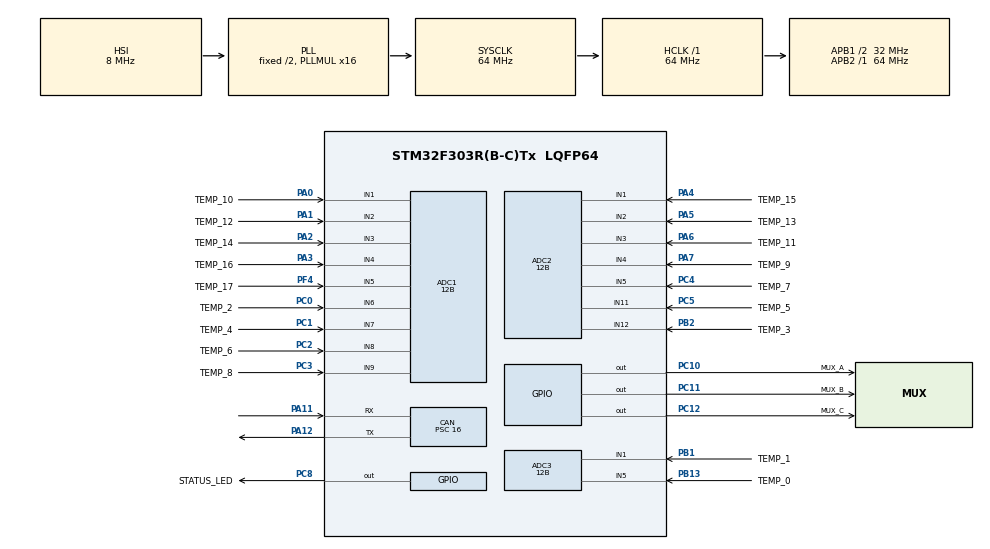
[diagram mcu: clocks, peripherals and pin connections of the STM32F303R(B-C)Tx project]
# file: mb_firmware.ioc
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ADC1.Channel-0\#ChannelRegularConversion=ADC_CHANNEL_6
ADC1.Channel-1\#ChannelRegularConversion=ADC_CHANNEL_7
ADC1.Channel-2\#ChannelRegularConversion=ADC_CHANNEL_8
ADC1.Channel-3\#ChannelRegularConversion=ADC_CHANNEL_9
ADC1.Channel-4\#ChannelRegularConversion=ADC_CHANNEL_1
ADC1.Channel-5\#ChannelRegularConversion=ADC_CHANNEL_2
ADC1.Channel-6\#ChannelRegularConversion=ADC_CHANNEL_3
ADC1.Channel-7\#ChannelRegularConversion=ADC_CHANNEL_4
ADC1.Channel-8\#ChannelRegularConversion=ADC_CHANNEL_5
ADC1.ClockPrescaler=ADC_CLOCK_ASYNC_DIV1
ADC1.ContinuousConvMode=DISABLE
ADC1.DMAContinuousRequests=DISABLE
ADC1.DataAlign=ADC_DATAALIGN_RIGHT
ADC1.DiscontinuousConvMode=DISABLE
ADC1.EOCSelection=ADC_EOC_SEQ_CONV
ADC1.EnableAnalogWatchDog1=false
ADC1.EnableAnalogWatchDog2=false
ADC1.EnableAnalogWatchDog3=false
ADC1.EnableInjectedConversion=ENABLE
ADC1.EnableRegularConversion=ENABLE
ADC1.ExternalTrigConv=ADC_SOFTWARE_START
ADC1.ExternalTrigConvEdge=ADC_EXTERNALTRIGCONVEDGE_NONE
ADC1.InjNumberOfConversion=0
ADC1.LowPowerAutoWait=DISABLE
ADC1.NbrOfConversion=9
ADC1.NbrOfConversionFlag=1
ADC1.Offset-0\#ChannelRegularConversion=0
ADC1.Offset-1\#ChannelRegularConversion=0
ADC1.Offset-2\#ChannelRegularConversion=0
ADC1.Offset-3\#ChannelRegularConversion=0
ADC1.Offset-4\#ChannelRegularConversion=0
ADC1.Offset-5\#ChannelRegularConversion=0
ADC1.Offset-6\#ChannelRegularConversion=0
ADC1.Offset-7\#ChannelRegularConversion=0
ADC1.Offset-8\#ChannelRegularConversion=0
ADC1.OffsetNumber-0\#ChannelRegularConversion=ADC_OFFSET_NONE
ADC1.OffsetNumber-1\#ChannelRegularConversion=ADC_OFFSET_NONE
ADC1.OffsetNumber-2\#ChannelRegularConversion=ADC_OFFSET_NONE
ADC1.OffsetNumber-3\#ChannelRegularConversion=ADC_OFFSET_NONE
ADC1.OffsetNumber-4\#ChannelRegularConversion=ADC_OFFSET_NONE
ADC1.OffsetNumber-5\#ChannelRegularConversion=ADC_OFFSET_NONE
ADC1.OffsetNumber-6\#ChannelRegularConversion=ADC_OFFSET_NONE
ADC1.OffsetNumber-7\#ChannelRegularConversion=ADC_OFFSET_NONE
ADC1.OffsetNumber-8\#ChannelRegularConversion=ADC_OFFSET_NONE
ADC1.Overrun=ADC_OVR_DATA_OVERWRITTEN
ADC1.Rank-0\#ChannelRegularConversion=1
ADC1.Rank-1\#ChannelRegularConversion=2
ADC1.Rank-2\#ChannelRegularConversion=3
ADC1.Rank-3\#ChannelRegularConversion=4
ADC1.Rank-4\#ChannelRegularConversion=5
ADC1.Rank-5\#ChannelRegularConversion=6
ADC1.Rank-6\#ChannelRegularConversion=7
ADC1.Rank-7\#ChannelRegularConversion=8
ADC1.Rank-8\#ChannelRegularConversion=9
ADC1.Resolution=ADC_RESOLUTION_12B
ADC1.SamplingTime-0\#ChannelRegularConversion=ADC_SAMPLETIME_19CYCLES_5
ADC1.SamplingTime-1\#ChannelRegularConversion=ADC_SAMPLETIME_19CYCLES_5
ADC1.SamplingTime-2\#ChannelRegularConversion=ADC_SAMPLETIME_19CYCLES_5
ADC1.SamplingTime-3\#ChannelRegularConversion=ADC_SAMPLETIME_19CYCLES_5
ADC1.SamplingTime-4\#ChannelRegularConversion=ADC_SAMPLETIME_19CYCLES_5
ADC1.SamplingTime-5\#ChannelRegularConversion=ADC_SAMPLETIME_19CYCLES_5
ADC1.SamplingTime-6\#ChannelRegularConversion=ADC_SAMPLETIME_19CYCLES_5
ADC1.SamplingTime-7\#ChannelRegularConversion=ADC_SAMPLETIME_19CYCLES_5
ADC1.SamplingTime-8\#ChannelRegularConversion=ADC_SAMPLETIME_19CYCLES_5
ADC1.ScanConvMode=ADC_SCAN_ENABLE
ADC1.master=1
ADC2.Channel-0\#ChannelRegularConversion=ADC_CHANNEL_12
ADC2.Channel-2\#ChannelRegularConversion=ADC_CHANNEL_11
ADC2.Channel-3\#ChannelRegularConversion=ADC_CHANNEL_5
ADC2.Channel-4\#ChannelRegularConversion=ADC_CHANNEL_4
ADC2.Channel-5\#ChannelRegularConversion=ADC_CHANNEL_3
ADC2.Channel-6\#ChannelRegularConversion=ADC_CHANNEL_2
ADC2.Channel-7\#ChannelRegularConversion=ADC_CHANNEL_1
ADC2.ClockPrescaler=ADC_CLOCK_ASYNC_DIV1
ADC2.ContinuousConvMode=DISABLE
ADC2.DMAContinuousRequests=DISABLE
ADC2.DataAlign=ADC_DATAALIGN_RIGHT
ADC2.DiscontinuousConvMode=DISABLE
ADC2.EOCSelection=ADC_EOC_SEQ_CONV
ADC2.EnableAnalogWatchDog1=false
ADC2.EnableAnalogWatchDog2=false
ADC2.EnableAnalogWatchDog3=false
ADC2.EnableInjectedConversion=ENABLE
ADC2.EnableRegularConversion=ENABLE
ADC2.ExternalTrigConv=ADC_SOFTWARE_START
ADC2.ExternalTrigConvEdge=ADC_EXTERNALTRIGCONVEDGE_NONE
ADC2.InjNumberOfConversion=0
ADC2.LowPowerAutoWait=DISABLE
ADC2.NbrOfConversion=7
ADC2.NbrOfConversionFlag=1
ADC2.Offset-0\#ChannelRegularConversion=0
ADC2.Offset-2\#ChannelRegularConversion=0
ADC2.Offset-3\#ChannelRegularConversion=0
ADC2.Offset-4\#ChannelRegularConversion=0
ADC2.Offset-5\#ChannelRegularConversion=0
ADC2.Offset-6\#ChannelRegularConversion=0
ADC2.Offset-7\#ChannelRegularConversion=0
ADC2.OffsetNumber-0\#ChannelRegularConversion=ADC_OFFSET_NONE
ADC2.OffsetNumber-2\#ChannelRegularConversion=ADC_OFFSET_NONE
ADC2.OffsetNumber-3\#ChannelRegularConversion=ADC_OFFSET_NONE
ADC2.OffsetNumber-4\#ChannelRegularConversion=ADC_OFFSET_NONE
ADC2.OffsetNumber-5\#ChannelRegularConversion=ADC_OFFSET_NONE
ADC2.OffsetNumber-6\#ChannelRegularConversion=ADC_OFFSET_NONE
ADC2.OffsetNumber-7\#ChannelRegularConversion=ADC_OFFSET_NONE
ADC2.Overrun=ADC_OVR_DATA_OVERWRITTEN
ADC2.Rank-0\#ChannelRegularConversion=1
ADC2.Rank-2\#ChannelRegularConversion=2
ADC2.Rank-3\#ChannelRegularConversion=3
ADC2.Rank-4\#ChannelRegularConversion=4
ADC2.Rank-5\#ChannelRegularConversion=5
ADC2.Rank-6\#ChannelRegularConversion=6
ADC2.Rank-7\#ChannelRegularConversion=7
ADC2.Resolution=ADC_RESOLUTION_12B
ADC2.SamplingTime-0\#ChannelRegularConversion=ADC_SAMPLETIME_19CYCLES_5
ADC2.SamplingTime-2\#ChannelRegularConversion=ADC_SAMPLETIME_19CYCLES_5
ADC2.SamplingTime-3\#ChannelRegularConversion=ADC_SAMPLETIME_19CYCLES_5
ADC2.SamplingTime-4\#ChannelRegularConversion=ADC_SAMPLETIME_19CYCLES_5
ADC2.SamplingTime-5\#ChannelRegularConversion=ADC_SAMPLETIME_19CYCLES_5
ADC2.SamplingTime-6\#ChannelRegularConversion=ADC_SAMPLETIME_19CYCLES_5
ADC2.SamplingTime-7\#ChannelRegularConversion=ADC_SAMPLETIME_19CYCLES_5
ADC2.ScanConvMode=ADC_SCAN_ENABLE
ADC3.Channel-0\#ChannelRegularConversion=ADC_CHANNEL_5
ADC3.Channel-1\#ChannelRegularConversion=ADC_CHANNEL_1
ADC3.ClockPrescaler=ADC_CLOCK_ASYNC_DIV1
ADC3.ContinuousConvMode=DISABLE
ADC3.DMAContinuousRequests=DISABLE
ADC3.DataAlign=ADC_DATAALIGN_RIGHT
ADC3.DiscontinuousConvMode=DISABLE
ADC3.EOCSelection=ADC_EOC_SEQ_CONV
ADC3.EnableAnalogWatchDog1=false
ADC3.EnableAnalogWatchDog2=false
ADC3.EnableAnalogWatchDog3=false
ADC3.EnableInjectedConversion=ENABLE
ADC3.EnableRegularConversion=ENABLE
ADC3.ExternalTrigConv=ADC_SOFTWARE_START
ADC3.ExternalTrigConvEdge=ADC_EXTERNALTRIGCONVEDGE_NONE
ADC3.InjNumberOfConversion=0
ADC3.LowPowerAutoWait=DISABLE
ADC3.NbrOfConversion=2
ADC3.NbrOfConversionFlag=1
ADC3.Offset-0\#ChannelRegularConversion=0
ADC3.Offset-1\#ChannelRegularConversion=0
ADC3.OffsetNumber-0\#ChannelRegularConversion=ADC_OFFSET_NONE
ADC3.OffsetNumber-1\#ChannelRegularConversion=ADC_OFFSET_NONE
ADC3.Overrun=ADC_OVR_DATA_OVERWRITTEN
ADC3.Rank-0\#ChannelRegularConversion=1
ADC3.Rank-1\#ChannelRegularConversion=2
ADC3.Resolution=ADC_RESOLUTION_12B
ADC3.SamplingTime-0\#ChannelRegularConversion=ADC_SAMPLETIME_19CYCLES_5
ADC3.SamplingTime-1\#ChannelRegularConversion=ADC_SAMPLETIME_19CYCLES_5
ADC3.ScanConvMode=ADC_SCAN_ENABLE
ADC3.master=1
CAN.BS1=CAN_BS1_13TQ
CAN.BS2=CAN_BS2_2TQ
CAN.CalculateTimeBit=8000
CAN.CalculateTimeQuantum=500.0
CAN.Prescaler=16
Dma.ADC1.0.Direction=DMA_PERIPH_TO_MEMORY
Dma.ADC1.0.Instance=DMA1_Channel1
Dma.ADC1.0.MemDataAlignment=DMA_MDATAALIGN_WORD
Dma.ADC1.0.MemInc=DMA_MINC_ENABLE
Dma.ADC1.0.Mode=DMA_CIRCULAR
Dma.ADC1.0.PeriphDataAlignment=DMA_PDATAALIGN_WORD
Dma.ADC1.0.PeriphInc=DMA_PINC_DISABLE
Dma.ADC1.0.Priority=DMA_PRIORITY_LOW
Dma.ADC2.2.Direction=DMA_PERIPH_TO_MEMORY
Dma.ADC2.2.Instance=DMA2_Channel1
Dma.ADC2.2.MemDataAlignment=DMA_MDATAALIGN_WORD
Dma.ADC2.2.MemInc=DMA_MINC_ENABLE
Dma.ADC2.2.Mode=DMA_CIRCULAR
Dma.ADC2.2.PeriphDataAlignment=DMA_PDATAALIGN_WORD
Dma.ADC2.2.PeriphInc=DMA_PINC_DISABLE
Dma.ADC2.2.Priority=DMA_PRIORITY_LOW
Dma.ADC3.1.Direction=DMA_PERIPH_TO_MEMORY
Dma.ADC3.1.Instance=DMA2_Channel5
Dma.ADC3.1.MemDataAlignment=DMA_MDATAALIGN_WORD
Dma.ADC3.1.MemInc=DMA_MINC_ENABLE
Dma.ADC3.1.Mode=DMA_CIRCULAR
Dma.ADC3.1.PeriphDataAlignment=DMA_PDATAALIGN_WORD
Dma.ADC3.1.PeriphInc=DMA_PINC_DISABLE
Dma.ADC3.1.Priority=DMA_PRIORITY_LOW
Dma.Request0=ADC1
Dma.Request1=ADC3
Dma.Request2=ADC2
Mcu.Family=STM32F3
Mcu.Name=STM32F303R(B-C)Tx
Mcu.Package=LQFP64
NVIC.DMA1_Channel1_IRQn=true\:0\:0\:false\:false\:true\:false
NVIC.DMA2_Channel1_IRQn=true\:0\:0\:false\:false\:true\:false
NVIC.DMA2_Channel5_IRQn=true\:0\:0\:false\:false\:true\:false
NVIC.PriorityGroup=NVIC_PRIORITYGROUP_4
NVIC.TIM2_IRQn=true\:0\:0\:false\:false\:true\:true
PA0.GPIO_Label=TEMP_10
PA0.Mode=IN1-Single-Ended
PA0.Signal=ADC1_IN1
PA1.GPIO_Label=TEMP_12
PA1.Mode=IN2-Single-Ended
PA1.Signal=ADC1_IN2
PA11.Mode=Master
PA11.Signal=CAN_RX
PA12.Mode=Master
PA12.Signal=CAN_TX
PA13.Mode=Serial_Wire
PA13.Signal=SYS_JTMS-SWDIO
PA14.Mode=Serial_Wire
PA14.Signal=SYS_JTCK-SWCLK
PA2.GPIO_Label=TEMP_14
PA2.Mode=IN3-Single-Ended
PA2.Signal=ADC1_IN3
PA3.GPIO_Label=TEMP_16
PA3.Mode=IN4-Single-Ended
PA3.Signal=ADC1_IN4
PA4.GPIO_Label=TEMP_15
PA4.Mode=IN1-Single-Ended
PA4.Signal=ADC2_IN1
PA5.GPIO_Label=TEMP_13
PA5.Mode=IN2-Single-Ended
PA5.Signal=ADC2_IN2
PA6.GPIO_Label=TEMP_11
PA6.Mode=IN3-Single-Ended
PA6.Signal=ADC2_IN3
PA7.GPIO_Label=TEMP_9
PA7.Mode=IN4-Single-Ended
PA7.Signal=ADC2_IN4
PB1.GPIO_Label=TEMP_1
PB1.Mode=IN1-Single-Ended
PB1.Signal=ADC3_IN1
PB13.GPIO_Label=TEMP_0
PB13.Mode=IN5-Single-Ended
PB13.Signal=ADC3_IN5
PB2.GPIO_Label=TEMP_3
PB2.Mode=IN12-Single-Ended
PB2.Signal=ADC2_IN12
PC0.GPIO_Label=TEMP_2
PC0.Signal=ADCx_IN6
PC1.GPIO_Label=TEMP_4
PC1.Signal=ADCx_IN7
PC10.GPIO_Label=MUX_A
PC10.Signal=GPIO_Output
PC11.GPIO_Label=MUX_B
PC11.Signal=GPIO_Output
PC12.GPIO_Label=MUX_C
PC12.Signal=GPIO_Output
PC2.GPIO_Label=TEMP_6
PC2.Signal=ADCx_IN8
PC3.GPIO_Label=TEMP_8
PC3.Signal=ADCx_IN9
PC4.GPIO_Label=TEMP_7
PC4.Mode=IN5-Single-Ended
PC4.Signal=ADC2_IN5
PC5.GPIO_Label=TEMP_5
PC5.Mode=IN11-Single-Ended
PC5.Signal=ADC2_IN11
PC8.GPIO_Label=STATUS_LED
PC8.Signal=GPIO_Output
PF4.GPIO_Label=TEMP_17
PF4.Mode=IN5-Single-Ended
PF4.Signal=ADC1_IN5
ProjectManager.HeapSize=0x200
ProjectManager.StackSize=0x400
ProjectManager.TargetToolchain=SW4STM32
RCC.AHBFreq_Value=64000000
RCC.APB1CLKDivider=RCC_HCLK_DIV2
RCC.APB1Freq_Value=32000000
RCC.APB1TimFreq_Value=64000000
RCC.APB2Freq_Value=64000000
RCC.APB2TimFreq_Value=64000000
RCC.CortexFreq_Value=64000000
RCC.HCLKFreq_Value=64000000
RCC.HSE_VALUE=8000000
RCC.HSI_VALUE=8000000
RCC.LSE_VALUE=32768
RCC.PLLMUL=RCC_PLL_MUL16
RCC.SYSCLKFreq_VALUE=64000000
RCC.SYSCLKSourceVirtual=RCC_SYSCLKSOURCE_PLLCLK
RCC.USBFreq_Value=64000000
SH.ADCx_IN6.0=ADC1_IN6,IN6-Single-Ended
SH.ADCx_IN7.0=ADC1_IN7,IN7-Single-Ended
SH.ADCx_IN8.0=ADC1_IN8,IN8-Single-Ended
SH.ADCx_IN9.0=ADC1_IN9,IN9-Single-Ended
TIM2.Period=63999
TIM2.Prescaler=249
VP_TIM2_VS_ClockSourceINT.Mode=Internal
board=mb_firmware

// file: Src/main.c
/**
  ******************************************************************************
  * File Name          : main.c
  * Description        : Main program body
  ******************************************************************************
  ** This notice applies to any and all portions of this file
  * that are not between comment pairs USER CODE BEGIN and
  * USER CODE END. Other portions of this file, whether
  * inserted by the user or by software development tools
  * are owned by their respective copyright owners.
  *
  * COPYRIGHT(c) 2017 STMicroelectronics
  *
  * Redistribution and use in source and binary forms, with or without modification,
  * are permitted provided that the following conditions are met:
  *   1. Redistributions of source code must retain the above copyright notice,
  *      this list of conditions and the following disclaimer.
  *   2. Redistributions in binary form must reproduce the above copyright notice,
  *      this list of conditions and the following disclaimer in the documentation
  *      and/or other materials provided with the distribution.
  *   3. Neither the name of STMicroelectronics nor the names of its contributors
  *      may be used to endorse or promote products derived from this software
  *      without specific prior written permission.
  *
  * THIS SOFTWARE IS PROVIDED BY THE COPYRIGHT HOLDERS AND CONTRIBUTORS "AS IS"
  * AND ANY EXPRESS OR IMPLIED WARRANTIES, INCLUDING, BUT NOT LIMITED TO, THE
  * IMPLIED WARRANTIES OF MERCHANTABILITY AND FITNESS FOR A PARTICULAR PURPOSE ARE
  * DISCLAIMED. IN NO EVENT SHALL THE COPYRIGHT HOLDER OR CONTRIBUTORS BE LIABLE
  * FOR ANY DIRECT, INDIRECT, INCIDENTAL, SPECIAL, EXEMPLARY, OR CONSEQUENTIAL
  * DAMAGES (INCLUDING, BUT NOT LIMITED TO, PROCUREMENT OF SUBSTITUTE GOODS OR
  * SERVICES; LOSS OF USE, DATA, OR PROFITS; OR BUSINESS INTERRUPTION) HOWEVER
  * CAUSED AND ON ANY THEORY OF LIABILITY, WHETHER IN CONTRACT, STRICT LIABILITY,
  * OR TORT (INCLUDING NEGLIGENCE OR OTHERWISE) ARISING IN ANY WAY OUT OF THE USE
  * OF THIS SOFTWARE, EVEN IF ADVISED OF THE POSSIBILITY OF SUCH DAMAGE.
  *
  ******************************************************************************
  */

#include "main.h"
#include "stm32f3xx_hal.h"

/* USER CODE BEGIN Includes */
#include "debug.h"
#include "temp.h"
/* USER CODE END Includes */

ADC_HandleTypeDef hadc1;
ADC_HandleTypeDef hadc2;
ADC_HandleTypeDef hadc3;
DMA_HandleTypeDef hdma_adc1;
DMA_HandleTypeDef hdma_adc2;
DMA_HandleTypeDef hdma_adc3;

CAN_HandleTypeDef hcan;

TIM_HandleTypeDef htim2;

/* USER CODE BEGIN PV */
/* Private variables ---------------------------------------------------------*/
extern int adc1_data_ready;
extern int adc2_data_ready;
extern int adc3_data_ready;
/* USER CODE END PV */

void SystemClock_Config(void);
static void MX_GPIO_Init(void);
static void MX_DMA_Init(void);
static void MX_ADC3_Init(void);
static void MX_ADC2_Init(void);
static void MX_ADC1_Init(void);
static void MX_CAN_Init(void);
static void MX_TIM2_Init(void);

/* USER CODE BEGIN PFP */
/* Private function prototypes -----------------------------------------------*/

/* USER CODE END PFP */

int main(void)
{

  /* MCU Configuration----------------------------------------------------------*/

  /* Reset of all peripherals, Initializes the Flash interface and the Systick. */
  HAL_Init();

  /* Configure the system clock */
  SystemClock_Config();

  /* Initialize all configured peripherals */
  MX_GPIO_Init();
  MX_DMA_Init();
  MX_ADC3_Init();
  MX_ADC2_Init();
  MX_ADC1_Init();
  MX_CAN_Init();
  MX_TIM2_Init();

  /* USER CODE BEGIN 2 */
  debug_init();
  temp_init();
  debug_log("I am alive!");
  /* USER CODE END 2 */

  /* Infinite loop */
  while (1)
  {

  /* USER CODE BEGIN 3 */
	  temp_process();

	  HAL_GPIO_TogglePin(STATUS_LED_GPIO_Port, STATUS_LED_Pin);
	  HAL_Delay(125);
  }
  /* USER CODE END 3 */

}

/** System Clock Configuration
*/
void SystemClock_Config(void)
{

  RCC_OscInitTypeDef RCC_OscInitStruct;
  RCC_ClkInitTypeDef RCC_ClkInitStruct;
  RCC_PeriphCLKInitTypeDef PeriphClkInit;

    /**Initializes the CPU, AHB and APB busses clocks
    */
  RCC_OscInitStruct.OscillatorType = RCC_OSCILLATORTYPE_HSI;
  RCC_OscInitStruct.HSIState = RCC_HSI_ON;
  RCC_OscInitStruct.HSICalibrationValue = 16;
  RCC_OscInitStruct.PLL.PLLState = RCC_PLL_ON;
  RCC_OscInitStruct.PLL.PLLSource = RCC_PLLSOURCE_HSI;
  RCC_OscInitStruct.PLL.PLLMUL = RCC_PLL_MUL16;
  if (HAL_RCC_OscConfig(&RCC_OscInitStruct) != HAL_OK)
  {
    _Error_Handler(__FILE__, __LINE__);
  }

    /**Initializes the CPU, AHB and APB busses clocks
    */
  RCC_ClkInitStruct.ClockType = RCC_CLOCKTYPE_HCLK|RCC_CLOCKTYPE_SYSCLK
                              |RCC_CLOCKTYPE_PCLK1|RCC_CLOCKTYPE_PCLK2;
  RCC_ClkInitStruct.SYSCLKSource = RCC_SYSCLKSOURCE_PLLCLK;
  RCC_ClkInitStruct.AHBCLKDivider = RCC_SYSCLK_DIV1;
  RCC_ClkInitStruct.APB1CLKDivider = RCC_HCLK_DIV2;
  RCC_ClkInitStruct.APB2CLKDivider = RCC_HCLK_DIV1;

  if (HAL_RCC_ClockConfig(&RCC_ClkInitStruct, FLASH_LATENCY_2) != HAL_OK)
  {
    _Error_Handler(__FILE__, __LINE__);
  }

  PeriphClkInit.PeriphClockSelection = RCC_PERIPHCLK_ADC12|RCC_PERIPHCLK_ADC34;
  PeriphClkInit.Adc12ClockSelection = RCC_ADC12PLLCLK_DIV1;
  PeriphClkInit.Adc34ClockSelection = RCC_ADC34PLLCLK_DIV1;
  if (HAL_RCCEx_PeriphCLKConfig(&PeriphClkInit) != HAL_OK)
  {
    _Error_Handler(__FILE__, __LINE__);
  }

    /**Configure the Systick interrupt time
    */
  HAL_SYSTICK_Config(HAL_RCC_GetHCLKFreq()/1000);

    /**Configure the Systick
    */
  HAL_SYSTICK_CLKSourceConfig(SYSTICK_CLKSOURCE_HCLK);

  /* SysTick_IRQn interrupt configuration */
  HAL_NVIC_SetPriority(SysTick_IRQn, 0, 0);
}

/* ADC1 init function */
static void MX_ADC1_Init(void)
{

  ADC_MultiModeTypeDef multimode;
  ADC_ChannelConfTypeDef sConfig;

    /**Common config
    */
  hadc1.Instance = ADC1;
  hadc1.Init.ClockPrescaler = ADC_CLOCK_ASYNC_DIV1;
  hadc1.Init.Resolution = ADC_RESOLUTION_12B;
  hadc1.Init.ScanConvMode = ADC_SCAN_ENABLE;
  hadc1.Init.ContinuousConvMode = DISABLE;
  hadc1.Init.DiscontinuousConvMode = DISABLE;
  hadc1.Init.ExternalTrigConvEdge = ADC_EXTERNALTRIGCONVEDGE_NONE;
  hadc1.Init.ExternalTrigConv = ADC_SOFTWARE_START;
  hadc1.Init.DataAlign = ADC_DATAALIGN_RIGHT;
  hadc1.Init.NbrOfConversion = 9;
  hadc1.Init.DMAContinuousRequests = DISABLE;
  hadc1.Init.EOCSelection = ADC_EOC_SEQ_CONV;
  hadc1.Init.LowPowerAutoWait = DISABLE;
  hadc1.Init.Overrun = ADC_OVR_DATA_OVERWRITTEN;
  if (HAL_ADC_Init(&hadc1) != HAL_OK)
  {
    _Error_Handler(__FILE__, __LINE__);
  }

    /**Configure the ADC multi-mode
    */
  multimode.Mode = ADC_MODE_INDEPENDENT;
  if (HAL_ADCEx_MultiModeConfigChannel(&hadc1, &multimode) != HAL_OK)
  {
    _Error_Handler(__FILE__, __LINE__);
  }

    /**Configure Regular Channel
    */
  sConfig.Channel = ADC_CHANNEL_6;
  sConfig.Rank = 1;
  sConfig.SingleDiff = ADC_SINGLE_ENDED;
  sConfig.SamplingTime = ADC_SAMPLETIME_19CYCLES_5;
  sConfig.OffsetNumber = ADC_OFFSET_NONE;
  sConfig.Offset = 0;
  if (HAL_ADC_ConfigChannel(&hadc1, &sConfig) != HAL_OK)
  {
    _Error_Handler(__FILE__, __LINE__);
  }

    /**Configure Regular Channel
    */
  sConfig.Channel = ADC_CHANNEL_7;
  sConfig.Rank = 2;
  if (HAL_ADC_ConfigChannel(&hadc1, &sConfig) != HAL_OK)
  {
    _Error_Handler(__FILE__, __LINE__);
  }

    /**Configure Regular Channel
    */
  sConfig.Channel = ADC_CHANNEL_8;
  sConfig.Rank = 3;
  if (HAL_ADC_ConfigChannel(&hadc1, &sConfig) != HAL_OK)
  {
    _Error_Handler(__FILE__, __LINE__);
  }

    /**Configure Regular Channel
    */
  sConfig.Channel = ADC_CHANNEL_9;
  sConfig.Rank = 4;
  if (HAL_ADC_ConfigChannel(&hadc1, &sConfig) != HAL_OK)
  {
    _Error_Handler(__FILE__, __LINE__);
  }

    /**Configure Regular Channel
    */
  sConfig.Channel = ADC_CHANNEL_1;
  sConfig.Rank = 5;
  if (HAL_ADC_ConfigChannel(&hadc1, &sConfig) != HAL_OK)
  {
    _Error_Handler(__FILE__, __LINE__);
  }

    /**Configure Regular Channel
    */
  sConfig.Channel = ADC_CHANNEL_2;
  sConfig.Rank = 6;
  if (HAL_ADC_ConfigChannel(&hadc1, &sConfig) != HAL_OK)
  {
    _Error_Handler(__FILE__, __LINE__);
  }

    /**Configure Regular Channel
    */
  sConfig.Channel = ADC_CHANNEL_3;
  sConfig.Rank = 7;
  if (HAL_ADC_ConfigChannel(&hadc1, &sConfig) != HAL_OK)
  {
    _Error_Handler(__FILE__, __LINE__);
  }

    /**Configure Regular Channel
    */
  sConfig.Channel = ADC_CHANNEL_4;
  sConfig.Rank = 8;
  if (HAL_ADC_ConfigChannel(&hadc1, &sConfig) != HAL_OK)
  {
    _Error_Handler(__FILE__, __LINE__);
  }

    /**Configure Regular Channel
    */
  sConfig.Channel = ADC_CHANNEL_5;
  sConfig.Rank = 9;
  if (HAL_ADC_ConfigChannel(&hadc1, &sConfig) != HAL_OK)
  {
    _Error_Handler(__FILE__, __LINE__);
  }

}

/* ADC2 init function */
static void MX_ADC2_Init(void)
{

  ADC_ChannelConfTypeDef sConfig;

    /**Common config
    */
  hadc2.Instance = ADC2;
  hadc2.Init.ClockPrescaler = ADC_CLOCK_ASYNC_DIV1;
  hadc2.Init.Resolution = ADC_RESOLUTION_12B;
  hadc2.Init.ScanConvMode = ADC_SCAN_ENABLE;
  hadc2.Init.ContinuousConvMode = DISABLE;
  hadc2.Init.DiscontinuousConvMode = DISABLE;
  hadc2.Init.ExternalTrigConvEdge = ADC_EXTERNALTRIGCONVEDGE_NONE;
  hadc2.Init.ExternalTrigConv = ADC_SOFTWARE_START;
  hadc2.Init.DataAlign = ADC_DATAALIGN_RIGHT;
  hadc2.Init.NbrOfConversion = 7;
  hadc2.Init.DMAContinuousRequests = DISABLE;
  hadc2.Init.EOCSelection = ADC_EOC_SEQ_CONV;
  hadc2.Init.LowPowerAutoWait = DISABLE;
  hadc2.Init.Overrun = ADC_OVR_DATA_OVERWRITTEN;
  if (HAL_ADC_Init(&hadc2) != HAL_OK)
  {
    _Error_Handler(__FILE__, __LINE__);
  }

    /**Configure Regular Channel
    */
  sConfig.Channel = ADC_CHANNEL_12;
  sConfig.Rank = 1;
  sConfig.SingleDiff = ADC_SINGLE_ENDED;
  sConfig.SamplingTime = ADC_SAMPLETIME_19CYCLES_5;
  sConfig.OffsetNumber = ADC_OFFSET_NONE;
  sConfig.Offset = 0;
  if (HAL_ADC_ConfigChannel(&hadc2, &sConfig) != HAL_OK)
  {
    _Error_Handler(__FILE__, __LINE__);
  }

    /**Configure Regular Channel
    */
  sConfig.Channel = ADC_CHANNEL_11;
  sConfig.Rank = 2;
  if (HAL_ADC_ConfigChannel(&hadc2, &sConfig) != HAL_OK)
  {
    _Error_Handler(__FILE__, __LINE__);
  }

    /**Configure Regular Channel
    */
  sConfig.Channel = ADC_CHANNEL_5;
  sConfig.Rank = 3;
  if (HAL_ADC_ConfigChannel(&hadc2, &sConfig) != HAL_OK)
  {
    _Error_Handler(__FILE__, __LINE__);
  }

    /**Configure Regular Channel
    */
  sConfig.Channel = ADC_CHANNEL_4;
  sConfig.Rank = 4;
  if (HAL_ADC_ConfigChannel(&hadc2, &sConfig) != HAL_OK)
  {
    _Error_Handler(__FILE__, __LINE__);
  }

    /**Configure Regular Channel
    */
  sConfig.Channel = ADC_CHANNEL_3;
  sConfig.Rank = 5;
  if (HAL_ADC_ConfigChannel(&hadc2, &sConfig) != HAL_OK)
  {
    _Error_Handler(__FILE__, __LINE__);
  }

    /**Configure Regular Channel
    */
  sConfig.Channel = ADC_CHANNEL_2;
  sConfig.Rank = 6;
  if (HAL_ADC_ConfigChannel(&hadc2, &sConfig) != HAL_OK)
  {
    _Error_Handler(__FILE__, __LINE__);
  }

    /**Configure Regular Channel
    */
  sConfig.Channel = ADC_CHANNEL_1;
  sConfig.Rank = 7;
  if (HAL_ADC_ConfigChannel(&hadc2, &sConfig) != HAL_OK)
  {
    _Error_Handler(__FILE__, __LINE__);
  }

}

/* ADC3 init function */
static void MX_ADC3_Init(void)
{

  ADC_MultiModeTypeDef multimode;
  ADC_ChannelConfTypeDef sConfig;

    /**Common config
    */
  hadc3.Instance = ADC3;
  hadc3.Init.ClockPrescaler = ADC_CLOCK_ASYNC_DIV1;
  hadc3.Init.Resolution = ADC_RESOLUTION_12B;
  hadc3.Init.ScanConvMode = ADC_SCAN_ENABLE;
  hadc3.Init.ContinuousConvMode = DISABLE;
  hadc3.Init.DiscontinuousConvMode = DISABLE;
  hadc3.Init.ExternalTrigConvEdge = ADC_EXTERNALTRIGCONVEDGE_NONE;
  hadc3.Init.ExternalTrigConv = ADC_SOFTWARE_START;
  hadc3.Init.DataAlign = ADC_DATAALIGN_RIGHT;
  hadc3.Init.NbrOfConversion = 2;
  hadc3.Init.DMAContinuousRequests = DISABLE;
  hadc3.Init.EOCSelection = ADC_EOC_SEQ_CONV;
  hadc3.Init.LowPowerAutoWait = DISABLE;
  hadc3.Init.Overrun = ADC_OVR_DATA_OVERWRITTEN;
  if (HAL_ADC_Init(&hadc3) != HAL_OK)
  {
    _Error_Handler(__FILE__, __LINE__);
  }

    /**Configure the ADC multi-mode
    */
  multimode.Mode = ADC_MODE_INDEPENDENT;
  if (HAL_ADCEx_MultiModeConfigChannel(&hadc3, &multimode) != HAL_OK)
  {
    _Error_Handler(__FILE__, __LINE__);
  }

    /**Configure Regular Channel
    */
  sConfig.Channel = ADC_CHANNEL_5;
  sConfig.Rank = 1;
  sConfig.SingleDiff = ADC_SINGLE_ENDED;
  sConfig.SamplingTime = ADC_SAMPLETIME_19CYCLES_5;
  sConfig.OffsetNumber = ADC_OFFSET_NONE;
  sConfig.Offset = 0;
  if (HAL_ADC_ConfigChannel(&hadc3, &sConfig) != HAL_OK)
  {
    _Error_Handler(__FILE__, __LINE__);
  }

    /**Configure Regular Channel
    */
  sConfig.Channel = ADC_CHANNEL_1;
  sConfig.Rank = 2;
  if (HAL_ADC_ConfigChannel(&hadc3, &sConfig) != HAL_OK)
  {
    _Error_Handler(__FILE__, __LINE__);
  }

}

/* CAN init function */
static void MX_CAN_Init(void)
{

  hcan.Instance = CAN;
  hcan.Init.Prescaler = 16;
  hcan.Init.Mode = CAN_MODE_NORMAL;
  hcan.Init.SJW = CAN_SJW_1TQ;
  hcan.Init.BS1 = CAN_BS1_13TQ;
  hcan.Init.BS2 = CAN_BS2_2TQ;
  hcan.Init.TTCM = DISABLE;
  hcan.Init.ABOM = DISABLE;
  hcan.Init.AWUM = DISABLE;
  hcan.Init.NART = DISABLE;
  hcan.Init.RFLM = DISABLE;
  hcan.Init.TXFP = DISABLE;
  if (HAL_CAN_Init(&hcan) != HAL_OK)
  {
    _Error_Handler(__FILE__, __LINE__);
  }

}

/* TIM2 init function */
static void MX_TIM2_Init(void)
{

  TIM_ClockConfigTypeDef sClockSourceConfig;
  TIM_MasterConfigTypeDef sMasterConfig;

  htim2.Instance = TIM2;
  htim2.Init.Prescaler = 249;
  htim2.Init.CounterMode = TIM_COUNTERMODE_UP;
  htim2.Init.Period = 63999;
  htim2.Init.ClockDivision = TIM_CLOCKDIVISION_DIV1;
  htim2.Init.AutoReloadPreload = TIM_AUTORELOAD_PRELOAD_DISABLE;
  if (HAL_TIM_Base_Init(&htim2) != HAL_OK)
  {
    _Error_Handler(__FILE__, __LINE__);
  }

  sClockSourceConfig.ClockSource = TIM_CLOCKSOURCE_INTERNAL;
  if (HAL_TIM_ConfigClockSource(&htim2, &sClockSourceConfig) != HAL_OK)
  {
    _Error_Handler(__FILE__, __LINE__);
  }

  sMasterConfig.MasterOutputTrigger = TIM_TRGO_RESET;
  sMasterConfig.MasterSlaveMode = TIM_MASTERSLAVEMODE_DISABLE;
  if (HAL_TIMEx_MasterConfigSynchronization(&htim2, &sMasterConfig) != HAL_OK)
  {
    _Error_Handler(__FILE__, __LINE__);
  }

}

static void MX_DMA_Init(void)
{
  /* DMA controller clock enable */
  __HAL_RCC_DMA1_CLK_ENABLE();
  __HAL_RCC_DMA2_CLK_ENABLE();

  /* DMA interrupt init */
  /* DMA1_Channel1_IRQn interrupt configuration */
  HAL_NVIC_SetPriority(DMA1_Channel1_IRQn, 0, 0);
  HAL_NVIC_EnableIRQ(DMA1_Channel1_IRQn);
  /* DMA2_Channel1_IRQn interrupt configuration */
  HAL_NVIC_SetPriority(DMA2_Channel1_IRQn, 0, 0);
  HAL_NVIC_EnableIRQ(DMA2_Channel1_IRQn);
  /* DMA2_Channel5_IRQn interrupt configuration */
  HAL_NVIC_SetPriority(DMA2_Channel5_IRQn, 0, 0);
  HAL_NVIC_EnableIRQ(DMA2_Channel5_IRQn);

}

/** Configure pins as
        * Analog
        * Input
        * Output
        * EVENT_OUT
        * EXTI
*/
static void MX_GPIO_Init(void)
{

  GPIO_InitTypeDef GPIO_InitStruct;

  /* GPIO Ports Clock Enable */
  __HAL_RCC_GPIOC_CLK_ENABLE();
  __HAL_RCC_GPIOA_CLK_ENABLE();
  __HAL_RCC_GPIOF_CLK_ENABLE();
  __HAL_RCC_GPIOB_CLK_ENABLE();

  /*Configure GPIO pin Output Level */
  HAL_GPIO_WritePin(GPIOC, STATUS_LED_Pin|MUX_A_Pin|MUX_B_Pin|MUX_C_Pin, GPIO_PIN_RESET);

  /*Configure GPIO pins : STATUS_LED_Pin MUX_A_Pin MUX_B_Pin MUX_C_Pin */
  GPIO_InitStruct.Pin = STATUS_LED_Pin|MUX_A_Pin|MUX_B_Pin|MUX_C_Pin;
  GPIO_InitStruct.Mode = GPIO_MODE_OUTPUT_PP;
  GPIO_InitStruct.Pull = GPIO_NOPULL;
  GPIO_InitStruct.Speed = GPIO_SPEED_FREQ_LOW;
  HAL_GPIO_Init(GPIOC, &GPIO_InitStruct);

}

void _Error_Handler(char * file, int line)
{
  /* USER CODE BEGIN Error_Handler_Debug */
  /* User can add his own implementation to report the HAL error return state */
  HAL_GPIO_WritePin(STATUS_LED_GPIO_Port, STATUS_LED_Pin, 1);
  while(1)
  {
  }
  /* USER CODE END Error_Handler_Debug */
}

/************************ (C) COPYRIGHT STMicroelectronics *****END OF FILE****/
